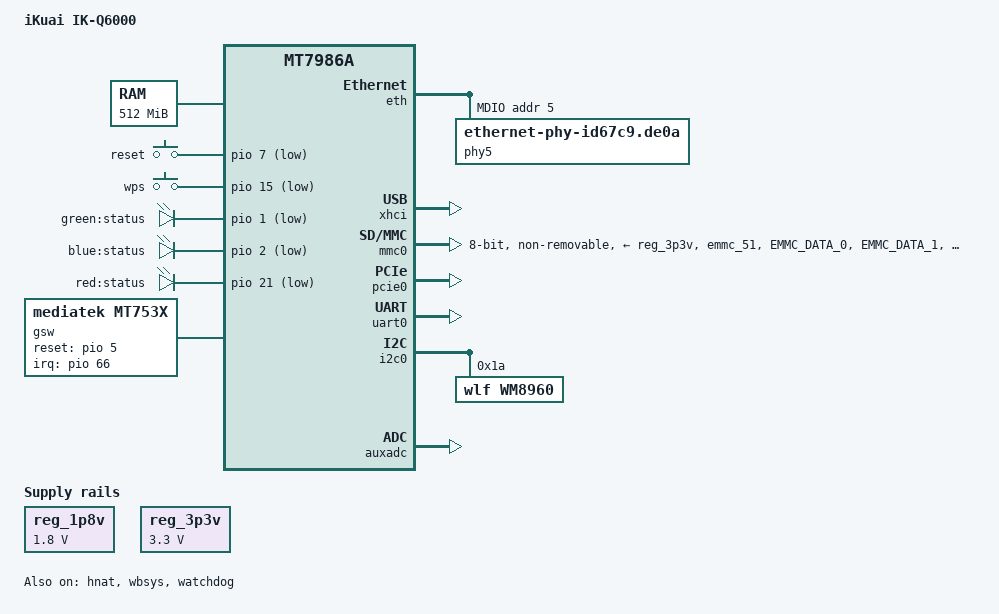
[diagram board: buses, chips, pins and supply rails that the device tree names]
// SPDX-License-Identifier: (GPL-2.0-only OR MIT)
/dts-v1/;

#include <dt-bindings/input/input.h>
#include <dt-bindings/gpio/gpio.h>
#include <dt-bindings/leds/common.h>

#include "mt7986a.dtsi"
#include "mt7986a-pinctrl.dtsi"
/ {
	model = "iKuai IK-Q6000";
	compatible = "ikuai,q6000", "mediatek,mt7986a";
	chosen {
		bootargs = "console=ttyS0,115200n1 loglevel=8  \
				earlycon=uart8250,mmio32,0x11002000";
	};
	
	aliases {
		led-boot = &led_red;
 		led-failsafe = &led_red;
 		led-running = &led_green;
 		led-upgrade = &led_blue;
	};

	memory {
		reg = <0 0x40000000 0 0x20000000>;
	};

        gpio-keys {
 		compatible = "gpio-keys";

 		button-reset {
 			label = "reset";
 			linux,code = <KEY_RESTART>;
 			gpios = <&pio 7 GPIO_ACTIVE_LOW>;
 		};

 		button-wps {
 			label = "wps";
 			linux,code = <KEY_WPS_BUTTON>;
 			gpios = <&pio 15 GPIO_ACTIVE_LOW>;
 		};
 	};

	leds {
		compatible = "gpio-leds";

		led_green: led-0 {
 			label = "green:status";
 			gpios = <&pio 1 GPIO_ACTIVE_LOW>;
 		};

 		led_blue: led-1 {
 			label = "blue:status";
 			gpios = <&pio 2 GPIO_ACTIVE_LOW>;
 		};
 			
		led_red: led-2 {
 			label = "red:status";
			gpios = <&pio 21 GPIO_ACTIVE_LOW>;
 		};
	};

	reg_1p8v: regulator-1p8v {
		compatible = "regulator-fixed";
		regulator-name = "fixed-1.8V";
		regulator-min-microvolt = <1800000>;
		regulator-max-microvolt = <1800000>;
		regulator-boot-on;
		regulator-always-on;
	};

	reg_3p3v: regulator-3p3v {
		compatible = "regulator-fixed";
		regulator-name = "fixed-3.3V";
		regulator-min-microvolt = <3300000>;
		regulator-max-microvolt = <3300000>;
		regulator-boot-on;
		regulator-always-on;
	};

	gsw: gsw@0 {
		compatible = "mediatek,mt753x";
		mediatek,ethsys = <&ethsys>;
		#address-cells = <1>;
		#size-cells = <0>;
	};
};

&eth {
	status = "okay";

	gmac0: mac@0 {
		compatible = "mediatek,eth-mac";
		reg = <0>;
		phy-mode = "2500base-x";

		fixed-link {
			speed = <2500>;
			full-duplex;
			pause;
		};
	};

	gmac1: mac@1 {
		compatible = "mediatek,eth-mac";
		reg = <1>;
		phy-mode = "2500base-x";

		ext-phy-reg = <3>;
		ext-phy-reset-gpios = <&pio 6 1>;

		fixed-link {
			speed = <2500>;
			full-duplex;
			pause;
		};
	};

	mdio: mdio-bus {
		#address-cells = <1>;
		#size-cells = <0>;

		phy5: phy@5 {
			compatible = "ethernet-phy-id67c9.de0a";
			reg = <5>;
		};
	};
};

&hnat {
	mtketh-wan = "eth1";
	mtketh-lan = "eth0";
	mtketh-max-gmac = <2>;
	status = "okay";
};

&gsw {
	mediatek,mdio = <&mdio>;
	mediatek,portmap = "lllll";
	mediatek,mdio_master_pinmux = <0>;
	reset-gpios = <&pio 5 0>;
	interrupt-parent = <&pio>;
	interrupts = <66 IRQ_TYPE_LEVEL_HIGH>;
	status = "okay";

	port5: port@5 {
		compatible = "mediatek,mt753x-port";
		reg = <5>;
		phy-mode = "sgmii";

		fixed-link {
			speed = <2500>;
			full-duplex;
		};
	};

	port6: port@6 {
		compatible = "mediatek,mt753x-port";
		mediatek,ssc-on;
		reg = <6>;
		phy-mode = "sgmii";
		fixed-link {
			speed = <2500>;
			full-duplex;
		};
	};
};

&xhci { 	
 	status = "okay";
};

&mmc0 {
	bus-width = <8>;
	cap-mmc-highspeed;
	hs400-ds-delay = <0x14014>;
	max-frequency = <200000000>;
	mmc-hs200-1_8v;
	mmc-hs400-1_8v;
	no-sd;
	no-sdio;
	non-removable;
	pinctrl-names = "default", "state_uhs";
	pinctrl-0 = <&mmc0_pins_default>;
	pinctrl-1 = <&mmc0_pins_uhs>;
	vmmc-supply = <&reg_3p3v>;
	vqmmc-supply = <&reg_1p8v>;
	status = "okay";
};

&pio {
	mmc0_pins_default: mmc0-pins-50-to-61-default {
		mux {
			function = "flash";
			groups = "emmc_51";
		};
		conf-cmd-dat {
			pins = "EMMC_DATA_0", "EMMC_DATA_1", "EMMC_DATA_2",
			       "EMMC_DATA_3", "EMMC_DATA_4", "EMMC_DATA_5",
			       "EMMC_DATA_6", "EMMC_DATA_7", "EMMC_CMD";
			input-enable;
			drive-strength = <MTK_DRIVE_4mA>;
			mediatek,pull-up-adv = <1>;	/* pull-up 10K */
		};
		conf-clk {
			pins = "EMMC_CK";
			drive-strength = <MTK_DRIVE_6mA>;
			mediatek,pull-down-adv = <2>;	/* pull-down 50K */
		};
		conf-ds {
			pins = "EMMC_DSL";
			mediatek,pull-down-adv = <2>;	/* pull-down 50K */
		};
		conf-rst {
			pins = "EMMC_RSTB";
			drive-strength = <MTK_DRIVE_4mA>;
			mediatek,pull-up-adv = <1>;	/* pull-up 10K */
		};
	};

	mmc0_pins_uhs: mmc0-pins-50-to-61-uhs {
		mux {
			function = "flash";
			groups = "emmc_51";
		};
		conf-cmd-dat {
			pins = "EMMC_DATA_0", "EMMC_DATA_1", "EMMC_DATA_2",
			       "EMMC_DATA_3", "EMMC_DATA_4", "EMMC_DATA_5",
			       "EMMC_DATA_6", "EMMC_DATA_7", "EMMC_CMD";
			input-enable;
			drive-strength = <MTK_DRIVE_4mA>;
			mediatek,pull-up-adv = <1>;	/* pull-up 10K */
		};
		conf-clk {
			pins = "EMMC_CK";
			drive-strength = <MTK_DRIVE_6mA>;
			mediatek,pull-down-adv = <2>;	/* pull-down 50K */
		};
		conf-ds {
			pins = "EMMC_DSL";
			mediatek,pull-down-adv = <2>;	/* pull-down 50K */
		};
		conf-rst {
			pins = "EMMC_RSTB";
			drive-strength = <MTK_DRIVE_4mA>;
			mediatek,pull-up-adv = <1>;	/* pull-up 10K */
		};
	};
};

&pcie0 {
    pinctrl-names = "default";
    pinctrl-0 = <&pcie0_pins>;
    status = "okay";
};

&uart0 {
    status = "okay";
};

&wbsys {
	pinctrl-names = "default";
	pinctrl-0 = <&wf_2g_5g_pins>;
	status = "okay";
};

&watchdog {
	status = "okay";
};

&i2c0 {
	pinctrl-names = "default";
	pinctrl-0 = <&i2c_pins>;
	status = "okay";

	wm8960: wm8960@1a {
		compatible = "wlf,wm8960";
		reg = <0x1a>;
	};
};

&auxadc {
	status = "okay";
};
